# PIC32MK1024GPK100 device description
Architecture: MIPS; Family: PIC32MK; Series: PIC32MK
Registers are 32-bit, read-write, no defined reset value unless marked. A register's access mark holds for its fields unless they carry their own. Offsets are from the block's base; [hi:lo] are bit positions; lines under a group give offsets from that group; {n}, {i} and the like mark numbered series.

## INT
Instances: INT 0x1f810000 in periph_pb1_fast
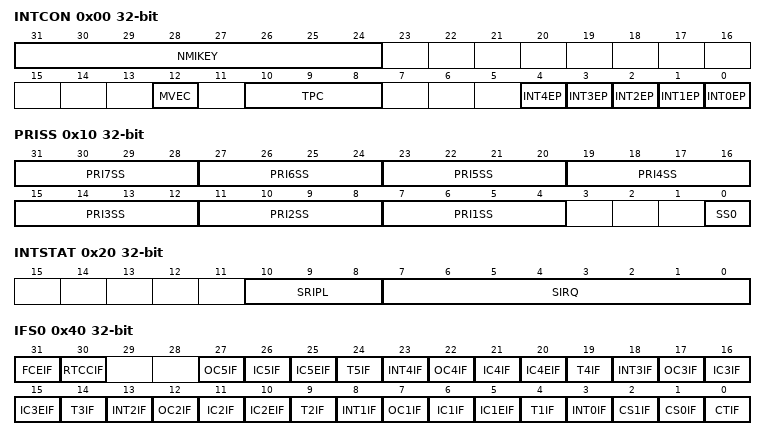
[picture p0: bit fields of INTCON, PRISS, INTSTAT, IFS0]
0x00 INTCON — Interrupt Control Register
  [31:24] NMIKEY
  [12] MVEC — Multi Vector Configuration bit
    1=Interrupt controller configured for multi vectored mode; 0=Interrupt controller configured for single vectored mode
  [10:8] TPC — Interrupt Proximity Timer Control bits
    {v}=Interrupts of group priority {v} or lower start the Interrupt Proximity timer (v=0..7)
  [n] INT{n}EP (n=0..4) — External Interrupt {n} Edge Polarity Control bit
    1=Rising edge; 0=Falling edge
0x10 PRISS — Priority shadow select register
  [31:28] PRI7SS — Interrupt with Priority Level 6 Shadow Set bits
    {v}=Interrupt with a priority level of 7 uses Shadow Set {v} (v=0..7)
  [4n+3:4n] PRI{n}SS (n=1..6) — Interrupt with Priority Level {n} Shadow Set bits
    {v}=Interrupt with a priority level of {n} uses Shadow Set {v} (v=0..7)
  [0] SS0 — Single Vector Shadow Register Set bit
    1=Single vector is presented with a shadow set; 0=Single vector is not presented with a shadow set
0x20 INTSTAT ro — Interrupt status register
  [10:8] SRIPL, [7:0] SIRQ
0x30 IPTMR — Interrupt proximity timer register
0x40 IFS0 — Interrupt flag status register
  [31] FCEIF, [30] RTCCIF, [5n+2] OC{n}IF (n=1..5), [5n+1] IC{n}IF (n=1..5), [5n] IC{n}EIF (n=1..5), [5n-1] T{n}IF (n=1..5), [5n+3] INT{n}IF (n=0..4), [2] CS1IF, [1] CS0IF, [0] CTIF
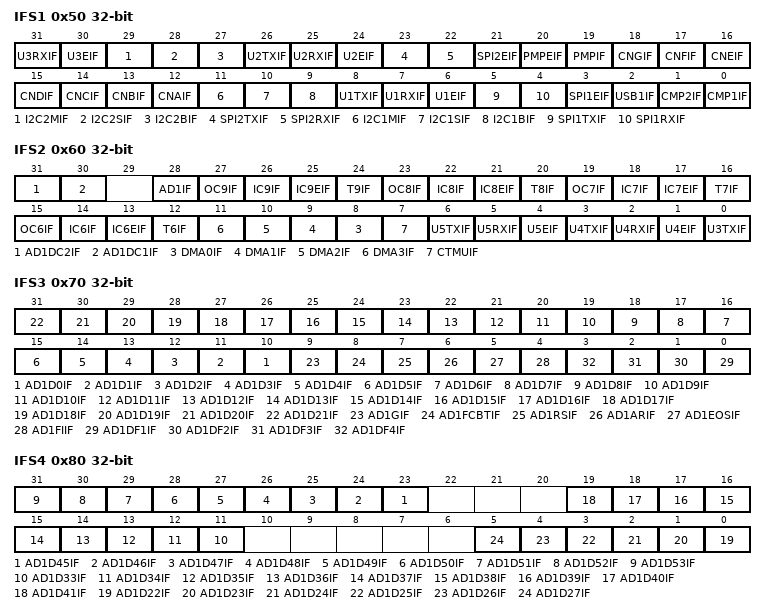
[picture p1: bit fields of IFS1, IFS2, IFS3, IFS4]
0x50 IFS1 — Interrupt flag status register
  [31] U3RXIF, [30] U3EIF, [29] I2C2MIF, [28] I2C2SIF, [27] I2C2BIF, [26] U2TXIF, [25] U2RXIF, [24] U2EIF, [23] SPI2TXIF, [22] SPI2RXIF, [21] SPI2EIF, [20] PMPEIF, [19] PMPIF, [18] CNGIF, [17] CNFIF, [16] CNEIF, [15] CNDIF, [14] CNCIF, [13] CNBIF, [12] CNAIF, [11] I2C1MIF, [10] I2C1SIF, [9] I2C1BIF, [8] U1TXIF, [7] U1RXIF, [6] U1EIF, [5] SPI1TXIF, [4] SPI1RXIF, [3] SPI1EIF, [2] USB1IF, [1] CMP2IF, [0] CMP1IF
0x60 IFS2 — Interrupt flag status register
  [31] AD1DC2IF, [30] AD1DC1IF, [28] AD1IF, [4n-9] OC{n}IF (n=6..9), [4n-10] IC{n}IF (n=6..9), [4n-11] IC{n}EIF (n=6..9), [4n-12] T{n}IF (n=6..9), [n+8] DMA{n}IF (n=0..3), [7] CTMUIF, [6] U5TXIF, [5] U5RXIF, [4] U5EIF, [3] U4TXIF, [2] U4RXIF, [1] U4EIF, [0] U3TXIF
0x70 IFS3 — Interrupt flag status register
  [n+10] AD1D{n}IF (n=0..21), [9] AD1GIF, [8] AD1FCBTIF, [7] AD1RSIF, [6] AD1ARIF, [5] AD1EOSIF, [4] AD1FIIF, [n-1] AD1DF{n}IF (n=1..4)
0x80 IFS4 — Interrupt flag status register
  [n-22] AD1D{n}IF (n=45..53), [n-22] AD1D{n}IF (n=33..41), [n-22] AD1D{n}IF (n=22..27)
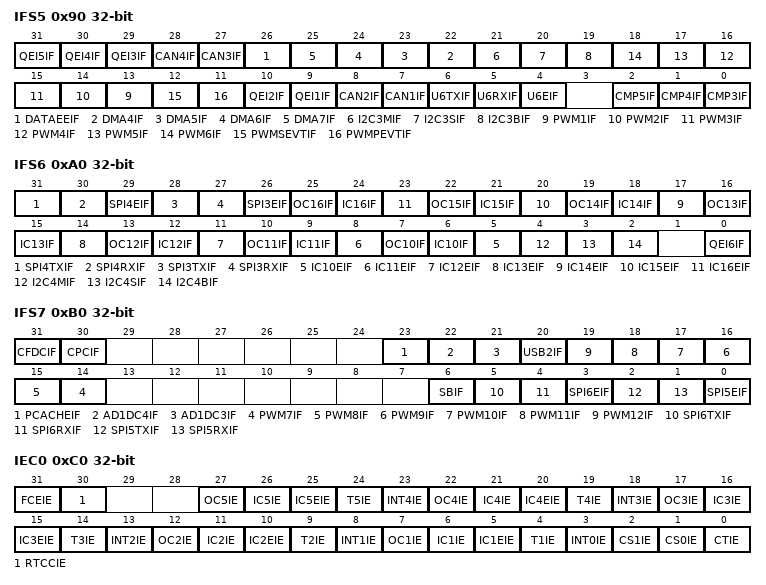
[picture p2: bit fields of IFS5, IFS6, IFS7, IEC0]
0x90 IFS5 — Interrupt flag status register
  [31] QEI5IF, [30] QEI4IF, [29] QEI3IF, [28] CAN4IF, [27] CAN3IF, [26] DATAEEIF, [n+18] DMA{n}IF (n=4..7), [21] I2C3MIF, [20] I2C3SIF, [19] I2C3BIF, [n+12] PWM{n}IF (n=1..6), [12] PWMSEVTIF, [11] PWMPEVTIF, [10] QEI2IF, [9] QEI1IF, [8] CAN2IF, [7] CAN1IF, [6] U6TXIF, [5] U6RXIF, [4] U6EIF, [2] CMP5IF, [1] CMP4IF, [0] CMP3IF
0xA0 IFS6 — Interrupt flag status register
  [31] SPI4TXIF, [30] SPI4RXIF, [29] SPI4EIF, [28] SPI3TXIF, [27] SPI3RXIF, [26] SPI3EIF, [3n-23] OC{n}IF (n=10..16), [3n-24] IC{n}IF (n=10..16), [3n-25] IC{n}EIF (n=10..16), [4] I2C4MIF, [3] I2C4SIF, [2] I2C4BIF, [0] QEI6IF
0xB0 IFS7 — Interrupt flag status register
  [31] CFDCIF, [30] CPCIF, [23] PCACHEIF, [22] AD1DC4IF, [21] AD1DC3IF, [20] USB2IF, [n+7] PWM{n}IF (n=7..12), [6] SBIF, [5] SPI6TXIF, [4] SPI6RXIF, [3] SPI6EIF, [2] SPI5TXIF, [1] SPI5RXIF, [0] SPI5EIF
0xC0 IEC0 — Interrupt enable control register
  [31] FCEIE, [30] RTCCIE, [5n+2] OC{n}IE (n=1..5), [5n+1] IC{n}IE (n=1..5), [5n] IC{n}EIE (n=1..5), [5n-1] T{n}IE (n=1..5), [5n+3] INT{n}IE (n=0..4), [2] CS1IE, [1] CS0IE, [0] CTIE
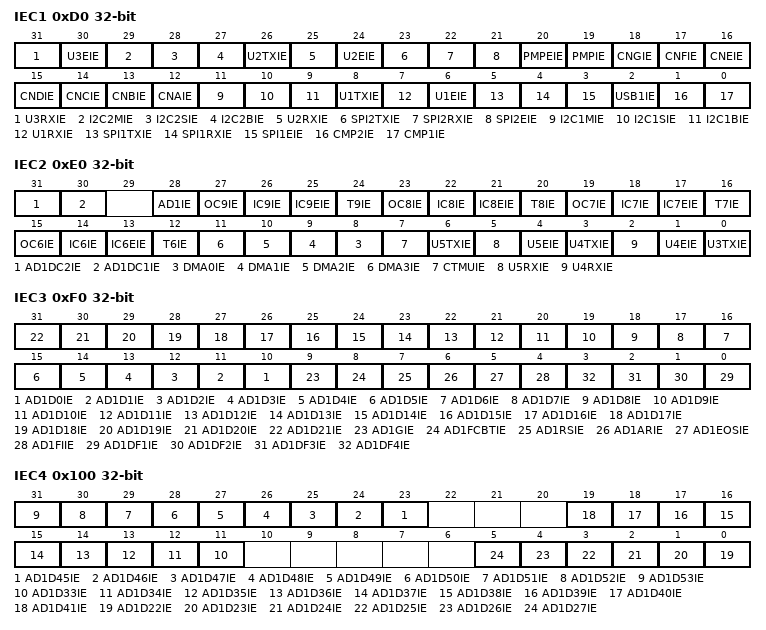
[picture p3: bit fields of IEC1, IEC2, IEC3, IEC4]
0xD0 IEC1 — Interrupt enable control register
  [31] U3RXIE, [30] U3EIE, [29] I2C2MIE, [28] I2C2SIE, [27] I2C2BIE, [26] U2TXIE, [25] U2RXIE, [24] U2EIE, [23] SPI2TXIE, [22] SPI2RXIE, [21] SPI2EIE, [20] PMPEIE, [19] PMPIE, [18] CNGIE, [17] CNFIE, [16] CNEIE, [15] CNDIE, [14] CNCIE, [13] CNBIE, [12] CNAIE, [11] I2C1MIE, [10] I2C1SIE, [9] I2C1BIE, [8] U1TXIE, [7] U1RXIE, [6] U1EIE, [5] SPI1TXIE, [4] SPI1RXIE, [3] SPI1EIE, [2] USB1IE, [1] CMP2IE, [0] CMP1IE
0xE0 IEC2 — Interrupt enable control register
  [31] AD1DC2IE, [30] AD1DC1IE, [28] AD1IE, [4n-9] OC{n}IE (n=6..9), [4n-10] IC{n}IE (n=6..9), [4n-11] IC{n}EIE (n=6..9), [4n-12] T{n}IE (n=6..9), [n+8] DMA{n}IE (n=0..3), [7] CTMUIE, [6] U5TXIE, [5] U5RXIE, [4] U5EIE, [3] U4TXIE, [2] U4RXIE, [1] U4EIE, [0] U3TXIE
0xF0 IEC3 — Interrupt enable control register
  [n+10] AD1D{n}IE (n=0..21), [9] AD1GIE, [8] AD1FCBTIE, [7] AD1RSIE, [6] AD1ARIE, [5] AD1EOSIE, [4] AD1FIIE, [n-1] AD1DF{n}IE (n=1..4)
0x100 IEC4 — Interrupt enable control register
  [n-22] AD1D{n}IE (n=45..53), [n-22] AD1D{n}IE (n=33..41), [n-22] AD1D{n}IE (n=22..27)
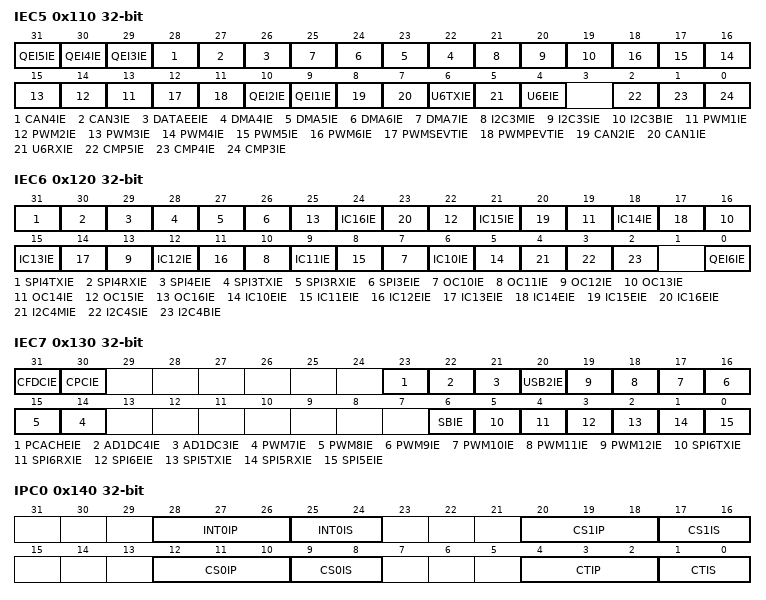
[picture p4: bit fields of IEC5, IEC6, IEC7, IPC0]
0x110 IEC5 — Interrupt enable control register
  [31] QEI5IE, [30] QEI4IE, [29] QEI3IE, [28] CAN4IE, [27] CAN3IE, [26] DATAEEIE, [n+18] DMA{n}IE (n=4..7), [21] I2C3MIE, [20] I2C3SIE, [19] I2C3BIE, [n+12] PWM{n}IE (n=1..6), [12] PWMSEVTIE, [11] PWMPEVTIE, [10] QEI2IE, [9] QEI1IE, [8] CAN2IE, [7] CAN1IE, [6] U6TXIE, [5] U6RXIE, [4] U6EIE, [2] CMP5IE, [1] CMP4IE, [0] CMP3IE
0x120 IEC6 — Interrupt enable control register
  [31] SPI4TXIE, [30] SPI4RXIE, [29] SPI4EIE, [28] SPI3TXIE, [27] SPI3RXIE, [26] SPI3EIE, [3n-23] OC{n}IE (n=10..16), [3n-24] IC{n}IE (n=10..16), [3n-25] IC{n}EIE (n=10..16), [4] I2C4MIE, [3] I2C4SIE, [2] I2C4BIE, [0] QEI6IE
0x130 IEC7 — Interrupt enable control register
  [31] CFDCIE, [30] CPCIE, [23] PCACHEIE, [22] AD1DC4IE, [21] AD1DC3IE, [20] USB2IE, [n+7] PWM{n}IE (n=7..12), [6] SBIE, [5] SPI6TXIE, [4] SPI6RXIE, [3] SPI6EIE, [2] SPI5TXIE, [1] SPI5RXIE, [0] SPI5EIE
0x140 IPC0 — Interrupt priority control register
  [28:26] INT0IP, [25:24] INT0IS, [20:18] CS1IP, [17:16] CS1IS, [12:10] CS0IP, [9:8] CS0IS, [4:2] CTIP, [1:0] CTIS
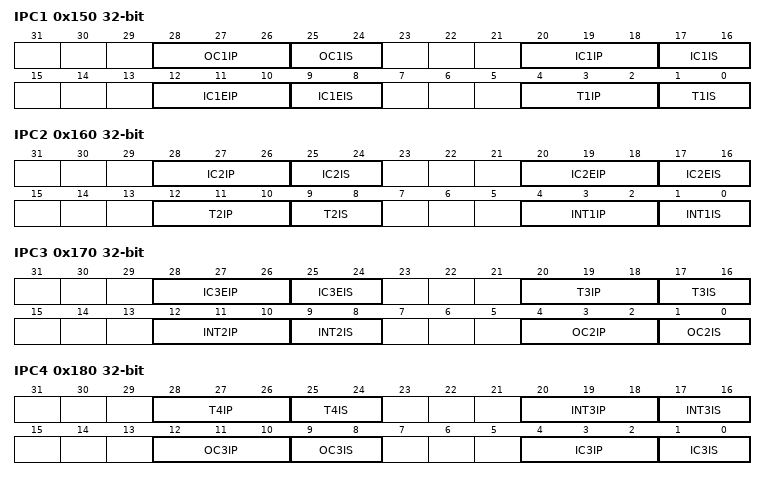
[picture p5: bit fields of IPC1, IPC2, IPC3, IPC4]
0x150 IPC1 — Interrupt priority control register
  [28:26] OC1IP, [25:24] OC1IS, [20:18] IC1IP, [17:16] IC1IS, [12:10] IC1EIP, [9:8] IC1EIS, [4:2] T1IP, [1:0] T1IS
0x160 IPC2 — Interrupt priority control register
  [28:26] IC2IP, [25:24] IC2IS, [20:18] IC2EIP, [17:16] IC2EIS, [12:10] T2IP, [9:8] T2IS, [4:2] INT1IP, [1:0] INT1IS
0x170 IPC3 — Interrupt priority control register
  [28:26] IC3EIP, [25:24] IC3EIS, [20:18] T3IP, [17:16] T3IS, [12:10] INT2IP, [9:8] INT2IS, [4:2] OC2IP, [1:0] OC2IS
0x180 IPC4 — Interrupt priority control register
  [28:26] T4IP, [25:24] T4IS, [20:18] INT3IP, [17:16] INT3IS, [12:10] OC3IP, [9:8] OC3IS, [4:2] IC3IP, [1:0] IC3IS
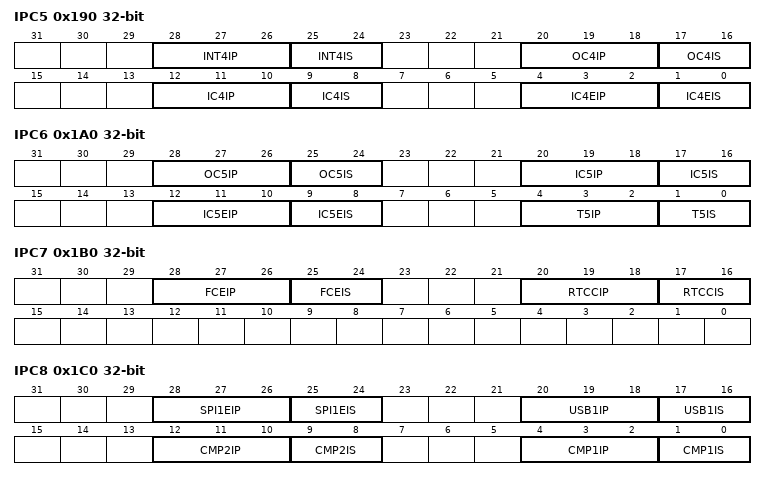
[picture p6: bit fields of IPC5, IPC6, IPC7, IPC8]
0x190 IPC5 — Interrupt priority control register
  [28:26] INT4IP, [25:24] INT4IS, [20:18] OC4IP, [17:16] OC4IS, [12:10] IC4IP, [9:8] IC4IS, [4:2] IC4EIP, [1:0] IC4EIS
0x1A0 IPC6 — Interrupt priority control register
  [28:26] OC5IP, [25:24] OC5IS, [20:18] IC5IP, [17:16] IC5IS, [12:10] IC5EIP, [9:8] IC5EIS, [4:2] T5IP, [1:0] T5IS
0x1B0 IPC7 — Interrupt priority control register
  [28:26] FCEIP, [25:24] FCEIS, [20:18] RTCCIP, [17:16] RTCCIS
0x1C0 IPC8 — Interrupt priority control register
  [28:26] SPI1EIP, [25:24] SPI1EIS, [20:18] USB1IP, [17:16] USB1IS, [12:10] CMP2IP, [9:8] CMP2IS, [4:2] CMP1IP, [1:0] CMP1IS
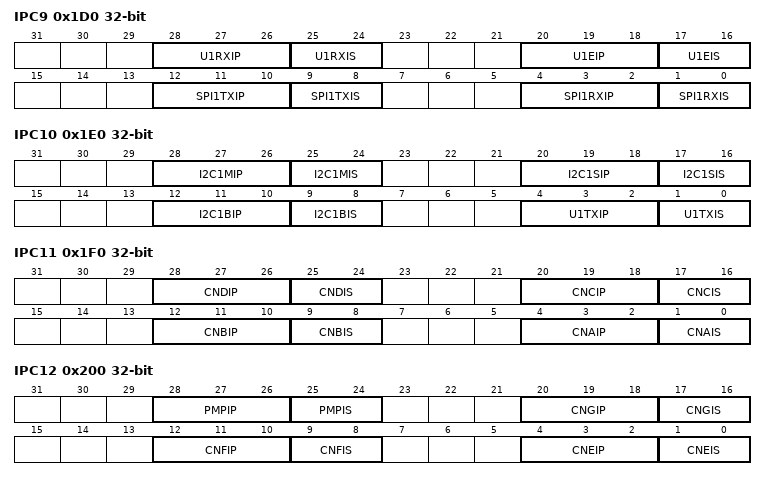
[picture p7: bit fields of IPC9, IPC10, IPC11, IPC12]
0x1D0 IPC9 — Interrupt priority control register
  [28:26] U1RXIP, [25:24] U1RXIS, [20:18] U1EIP, [17:16] U1EIS, [12:10] SPI1TXIP, [9:8] SPI1TXIS, [4:2] SPI1RXIP, [1:0] SPI1RXIS
0x1E0 IPC10 — Interrupt priority control register
  [28:26] I2C1MIP, [25:24] I2C1MIS, [20:18] I2C1SIP, [17:16] I2C1SIS, [12:10] I2C1BIP, [9:8] I2C1BIS, [4:2] U1TXIP, [1:0] U1TXIS
0x1F0 IPC11 — Interrupt priority control register
  [28:26] CNDIP, [25:24] CNDIS, [20:18] CNCIP, [17:16] CNCIS, [12:10] CNBIP, [9:8] CNBIS, [4:2] CNAIP, [1:0] CNAIS
0x200 IPC12 — Interrupt priority control register
  [28:26] PMPIP, [25:24] PMPIS, [20:18] CNGIP, [17:16] CNGIS, [12:10] CNFIP, [9:8] CNFIS, [4:2] CNEIP, [1:0] CNEIS
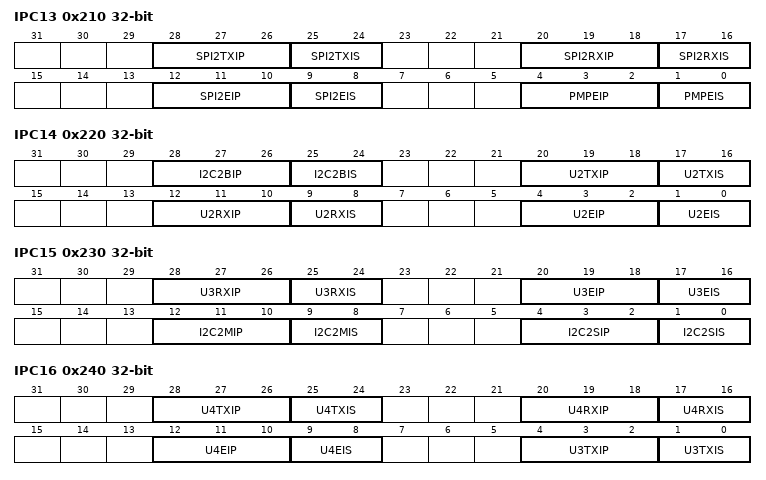
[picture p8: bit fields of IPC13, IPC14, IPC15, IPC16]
0x210 IPC13 — Interrupt priority control register
  [28:26] SPI2TXIP, [25:24] SPI2TXIS, [20:18] SPI2RXIP, [17:16] SPI2RXIS, [12:10] SPI2EIP, [9:8] SPI2EIS, [4:2] PMPEIP, [1:0] PMPEIS
0x220 IPC14 — Interrupt priority control register
  [28:26] I2C2BIP, [25:24] I2C2BIS, [20:18] U2TXIP, [17:16] U2TXIS, [12:10] U2RXIP, [9:8] U2RXIS, [4:2] U2EIP, [1:0] U2EIS
0x230 IPC15 — Interrupt priority control register
  [28:26] U3RXIP, [25:24] U3RXIS, [20:18] U3EIP, [17:16] U3EIS, [12:10] I2C2MIP, [9:8] I2C2MIS, [4:2] I2C2SIP, [1:0] I2C2SIS
0x240 IPC16 — Interrupt priority control register
  [28:26] U4TXIP, [25:24] U4TXIS, [20:18] U4RXIP, [17:16] U4RXIS, [12:10] U4EIP, [9:8] U4EIS, [4:2] U3TXIP, [1:0] U3TXIS
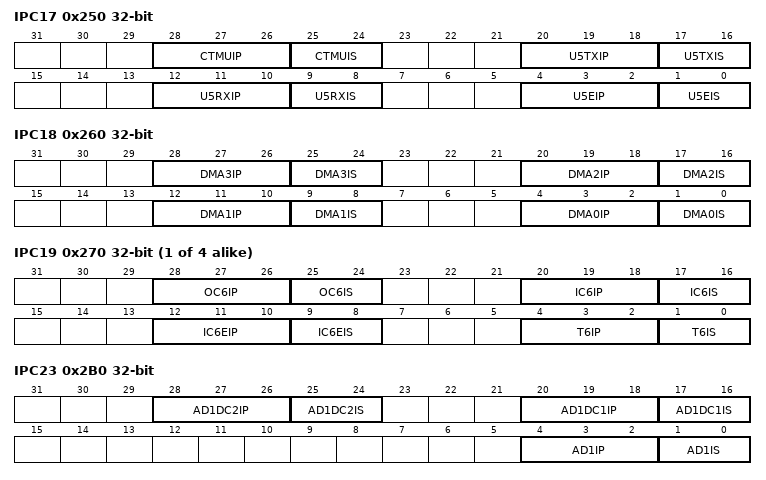
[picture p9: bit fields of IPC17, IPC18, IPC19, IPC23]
0x250 IPC17 — Interrupt priority control register
  [28:26] CTMUIP, [25:24] CTMUIS, [20:18] U5TXIP, [17:16] U5TXIS, [12:10] U5RXIP, [9:8] U5RXIS, [4:2] U5EIP, [1:0] U5EIS
0x260 IPC18 — Interrupt priority control register
  [8n+4:8n+2] DMA{n}IP (n=0..3), [8n+1:8n] DMA{n}IS (n=0..3)
{0x140+0x10*i} IPC{i} (i=19..22) — Interrupt priority control register
  [28:26] OC{i-13}IP, [25:24] OC{i-13}IS, [20:18] IC{i-13}IP, [17:16] IC{i-13}IS, [12:10] IC{i-13}EIP, [9:8] IC{i-13}EIS, [4:2] T{i-13}IP, [1:0] T{i-13}IS
0x2B0 IPC23 — Interrupt priority control register
  [28:26] AD1DC2IP, [25:24] AD1DC2IS, [20:18] AD1DC1IP, [17:16] AD1DC1IS, [4:2] AD1IP, [1:0] AD1IS
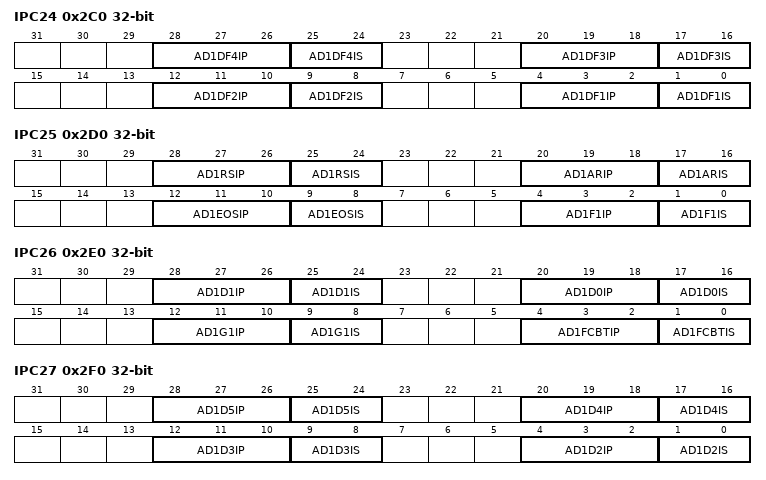
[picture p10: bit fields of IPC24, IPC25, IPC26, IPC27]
0x2C0 IPC24 — Interrupt priority control register
  [8n-4:8n-6] AD1DF{n}IP (n=1..4), [8n-7:8n-8] AD1DF{n}IS (n=1..4)
0x2D0 IPC25 — Interrupt priority control register
  [28:26] AD1RSIP, [25:24] AD1RSIS, [20:18] AD1ARIP, [17:16] AD1ARIS, [12:10] AD1EOSIP, [9:8] AD1EOSIS, [4:2] AD1F1IP, [1:0] AD1F1IS
0x2E0 IPC26 — Interrupt priority control register
  [28:26] AD1D1IP, [25:24] AD1D1IS, [20:18] AD1D0IP, [17:16] AD1D0IS, [12:10] AD1G1IP, [9:8] AD1G1IS, [4:2] AD1FCBTIP, [1:0] AD1FCBTIS
0x2F0 IPC27 — Interrupt priority control register
  [8n-12:8n-14] AD1D{n}IP (n=2..5), [8n-15:8n-16] AD1D{n}IS (n=2..5)
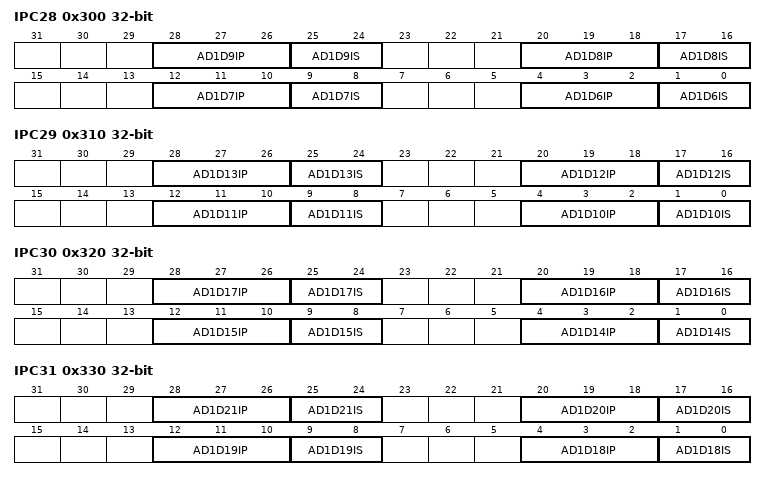
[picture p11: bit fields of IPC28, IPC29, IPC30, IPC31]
0x300 IPC28 — Interrupt priority control register
  [8n-44:8n-46] AD1D{n}IP (n=6..9), [8n-47:8n-48] AD1D{n}IS (n=6..9)
0x310 IPC29 — Interrupt priority control register
  [8n-76:8n-78] AD1D{n}IP (n=10..13), [8n-79:8n-80] AD1D{n}IS (n=10..13)
0x320 IPC30 — Interrupt priority control register
  [8n-108:8n-110] AD1D{n}IP (n=14..17), [8n-111:8n-112] AD1D{n}IS (n=14..17)
0x330 IPC31 — Interrupt priority control register
  [8n-140:8n-142] AD1D{n}IP (n=18..21), [8n-143:8n-144] AD1D{n}IS (n=18..21)
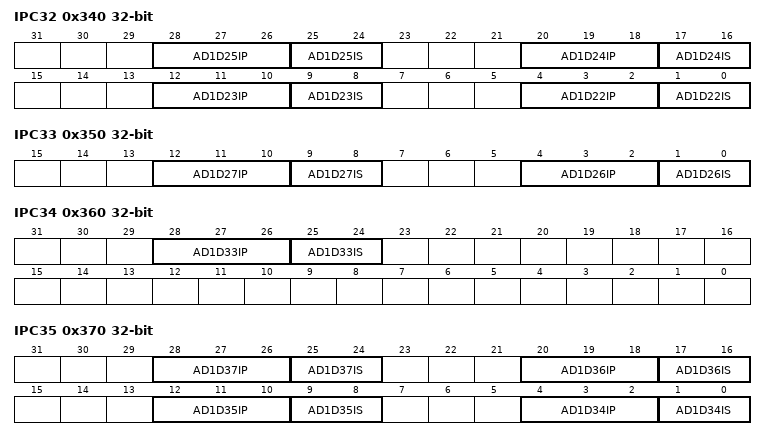
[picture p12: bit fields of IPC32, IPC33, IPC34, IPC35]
0x340 IPC32 — Interrupt priority control register
  [8n-172:8n-174] AD1D{n}IP (n=22..25), [8n-175:8n-176] AD1D{n}IS (n=22..25)
0x350 IPC33 — Interrupt priority control register
  [12:10] AD1D27IP, [9:8] AD1D27IS, [4:2] AD1D26IP, [1:0] AD1D26IS
0x360 IPC34 — Interrupt priority control register
  [28:26] AD1D33IP, [25:24] AD1D33IS
0x370 IPC35 — Interrupt priority control register
  [8n-268:8n-270] AD1D{n}IP (n=34..37), [8n-271:8n-272] AD1D{n}IS (n=34..37)
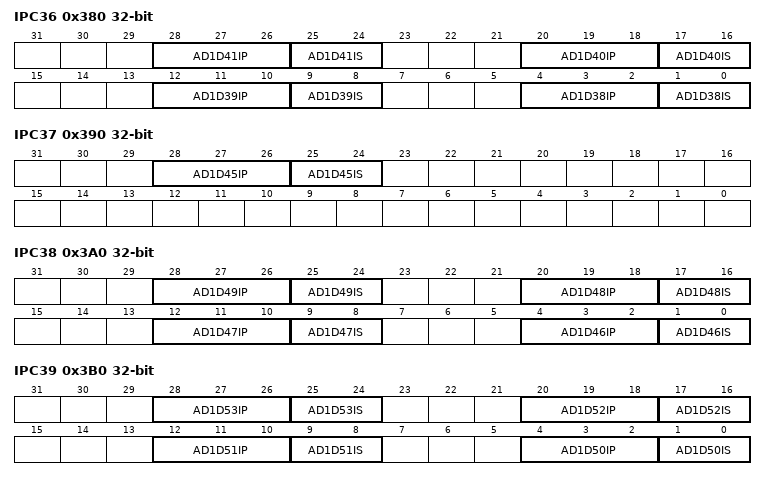
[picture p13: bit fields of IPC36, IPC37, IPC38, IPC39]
0x380 IPC36 — Interrupt priority control register
  [8n-300:8n-302] AD1D{n}IP (n=38..41), [8n-303:8n-304] AD1D{n}IS (n=38..41)
0x390 IPC37 — Interrupt priority control register
  [28:26] AD1D45IP, [25:24] AD1D45IS
0x3A0 IPC38 — Interrupt priority control register
  [8n-364:8n-366] AD1D{n}IP (n=46..49), [8n-367:8n-368] AD1D{n}IS (n=46..49)
0x3B0 IPC39 — Interrupt priority control register
  [8n-396:8n-398] AD1D{n}IP (n=50..53), [8n-399:8n-400] AD1D{n}IS (n=50..53)
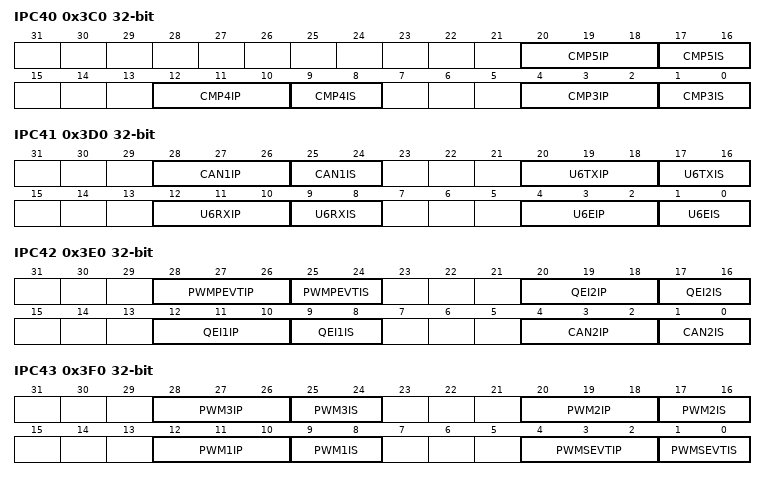
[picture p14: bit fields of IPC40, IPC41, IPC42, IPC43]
0x3C0 IPC40 — Interrupt priority control register
  [20:18] CMP5IP, [17:16] CMP5IS, [12:10] CMP4IP, [9:8] CMP4IS, [4:2] CMP3IP, [1:0] CMP3IS
0x3D0 IPC41 — Interrupt priority control register
  [28:26] CAN1IP, [25:24] CAN1IS, [20:18] U6TXIP, [17:16] U6TXIS, [12:10] U6RXIP, [9:8] U6RXIS, [4:2] U6EIP, [1:0] U6EIS
0x3E0 IPC42 — Interrupt priority control register
  [28:26] PWMPEVTIP, [25:24] PWMPEVTIS, [20:18] QEI2IP, [17:16] QEI2IS, [12:10] QEI1IP, [9:8] QEI1IS, [4:2] CAN2IP, [1:0] CAN2IS
0x3F0 IPC43 — Interrupt priority control register
  [28:26] PWM3IP, [25:24] PWM3IS, [20:18] PWM2IP, [17:16] PWM2IS, [12:10] PWM1IP, [9:8] PWM1IS, [4:2] PWMSEVTIP, [1:0] PWMSEVTIS
0x400 IPC44 — Interrupt priority control register
  [28:26] I2C3BIP, [25:24] I2C3BIS, [20:18] PWM6IP, [17:16] PWM6IS, [12:10] PWM5IP, [9:8] PWM5IS, [4:2] PWM4IP, [1:0] PWM4IS
0x410 IPC45 — Interrupt priority control register
  [28:26] DMA5IP, [25:24] DMA5IS, [20:18] DMA4IP, [17:16] DMA4IS, [12:10] I2C3MIP, [9:8] I2C3MIS, [4:2] I2C3SIP, [1:0] I2C3SIS
0x420 IPC46 — Interrupt priority control register
  [28:26] CAN3IP, [25:24] CAN3IS, [20:18] DATAEEIP, [17:16] DATAEEIS, [12:10] DMA7IP, [9:8] DMA7IS, [4:2] DMA6IP, [1:0] DMA6IS
0x430 IPC47 — Interrupt priority control register
  [28:26] QEI5IP, [25:24] QEI5IS, [20:18] QEI4IP, [17:16] QEI4IS, [12:10] QEI3IP, [9:8] QEI3IS, [4:2] CAN4IP, [1:0] CAN4IS
0x440 IPC48 — Interrupt priority control register
  [28:26] I2C4SIP, [25:24] I2C4SIS, [20:18] I2C4BIP, [17:16] I2C4BIS, [4:2] QEI6IP, [1:0] QEI6IS
0x450 IPC49 — Interrupt priority control register
  [28:26] OC10IP, [25:24] OC10IS, [20:18] IC10IP, [17:16] IC10IS, [12:10] IC10EIP, [9:8] IC10EIS, [4:2] I2C4MIP, [1:0] I2C4MIS
0x460 IPC50 — Interrupt priority control register
  [28:26] IC12EIP, [25:24] IC12EIS, [20:18] OC11IP, [17:16] OC11IS, [12:10] IC11IP, [9:8] IC11IS, [4:2] IC11EIP, [1:0] IC11EIS
0x470 IPC51 — Interrupt priority control register
  [28:26] IC13IP, [25:24] IC13IS, [20:18] IC13EIP, [17:16] IC13EIS, [12:10] OC12IP, [9:8] OC12IS, [4:2] IC12IP, [1:0] IC12IS
0x480 IPC52 — Interrupt priority control register
  [28:26] OC14IP, [25:24] OC14IS, [20:18] IC14IP, [17:16] IC14IS, [12:10] IC14EIP, [9:8] IC14EIS, [4:2] OC13IP, [1:0] OC13IS
0x490 IPC53 — Interrupt priority control register
  [28:26] IC16EIP, [25:24] IC16EIS, [20:18] OC15IP, [17:16] OC15IS, [12:10] IC15IP, [9:8] IC15IS, [4:2] IC15EIP, [1:0] IC15EIS
0x4A0 IPC54 — Interrupt priority control register
  [28:26] SPI3RXIP, [25:24] SPI3RXIS, [20:18] SPI3EIP, [17:16] SPI3EIS, [12:10] OC16IP, [9:8] OC16IS, [4:2] IC16IP, [1:0] IC16IS
0x4B0 IPC55 — Interrupt priority control register
  [28:26] SPI4TXIP, [25:24] SPI4TXIS, [20:18] SPI4RXIP, [17:16] SPI4RXIS, [12:10] SPI4EIP, [9:8] SPI4EIS, [4:2] SPI3TXIP, [1:0] SPI3TXIS
0x4C0 IPC56 — Interrupt priority control register
  [28:26] SPI6EIP, [25:24] SPI6EIS, [20:18] SPI5TXIP, [17:16] SPI5TXIS, [12:10] SPI5RXIP, [9:8] SPI5RXIS, [4:2] SPI5EIP, [1:0] SPI5EIS
0x4D0 IPC57 — Interrupt priority control register
  [20:18] SBIP, [17:16] SBIS, [12:10] SPI6TXIP, [9:8] SPI6TXIS, [4:2] SPI6RXIP, [1:0] SPI6RXIS
0x4E0 IPC58 ro — Interrupt priority control register
0x4F0 IPC59 — Interrupt priority control register
  [28:26] PWM8IP, [25:24] PWM8IS, [20:18] PWM7IP, [17:16] PWM7IS
0x500 IPC60 — Interrupt priority control register
  [8n-68:8n-70] PWM{n}IP (n=9..12), [8n-71:8n-72] PWM{n}IS (n=9..12)
0x510 IPC61 — Interrupt priority control register
  [28:26] PCACHEIP, [25:24] PCACHEIS, [20:18] AD1DC4IP, [17:16] AD1DC4IS, [12:10] AD1DC3IP, [9:8] AD1DC3IS, [4:2] USB2IP, [1:0] USB2IS
0x520 IPC62 ro — Interrupt priority control register
0x530 IPC63 — Interrupt priority control register
  [28:26] CFDCIP, [25:24] CFDCIS, [20:18] CPCIP, [17:16] CPCIS
{0x540+4i} OFF{i:03} (i=0..27) — Interrupt vector address offset register
  [17:1] VOFF
{0x540+4i} OFF{i:03} (i=30..44) — Interrupt vector address offset register
  [17:1] VOFF
0x5EC OFF045 — Interrupt vector address offset register
  [17:1] VOFF
{0x540+4i} OFF{i:03} (i=46..50) — Interrupt vector address offset register
  [17:1] VOFF
{0x544+4i} OFF{i:03} (i=51..57) — Interrupt vector address offset register
  [17:1] VOFF
0x620 OFF058 — Interrupt vector address offset register
  [17:1] VOFF
{0x540+4i} OFF{i:03} (i=59..92) — Interrupt vector address offset register
  [17:1] VOFF
{0x540+4i} OFF{i:03} (i=94..107) — Interrupt vector address offset register
  [17:1] VOFF
0x6E4 OFF108 — Interrupt vector address offset register
  [17:1] VOFF
{0x540+4i} OFF{i} (i=109..133) — Interrupt vector address offset register
  [17:1] VOFF
{0x540+4i} OFF{i} (i=139..147) — Interrupt vector address offset register
  [17:1] VOFF
0x788 OFF157 — Interrupt vector address offset register
  [17:1] VOFF
{0x540+4i} OFF{i} (i=151..156) — Interrupt vector address offset register
  [17:1] VOFF
{0x510+4i} OFF{i} (i=169..178) — Interrupt vector address offset register
  [17:1] VOFF
{0x540+4i} OFF{i} (i=158..162) — Interrupt vector address offset register
  [17:1] VOFF
{0x540+4i} OFF{i} (i=164..168) — Interrupt vector address offset register
  [17:1] VOFF
{0x510+4i} OFF{i} (i=189..192) — Interrupt vector address offset register
  [17:1] VOFF
{0x540+4i} OFF{i} (i=179..188) — Interrupt vector address offset register
  [17:1] VOFF
{0x50C+4i} OFF{i} (i=199..221) — Interrupt vector address offset register
  [17:1] VOFF
{0x540+4i} OFF{i} (i=194..198) — Interrupt vector address offset register
  [17:1] VOFF
{0x50C+4i} OFF{i} (i=222..229)
  [17:1] VOFF
0x8B4 OFF247
  [17:1] VOFF
0x8BC OFF255
  [17:1] VOFF
0x8D8 OFF230
  [17:1] VOFF
{0x540+4i} OFF{i} (i=244..246)
  [17:1] VOFF
0x938 OFF254
  [17:1] VOFF
